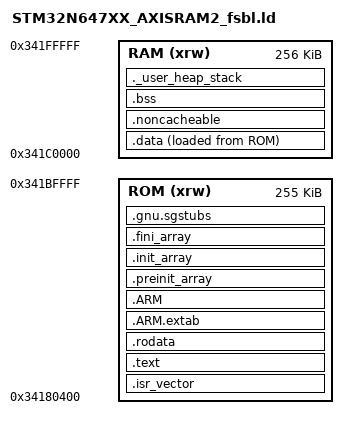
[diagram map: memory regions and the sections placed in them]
/*
******************************************************************************
**
** @file        : STM32N647XX_AXISRAM2_fsbl.ld
**
** @author      : GPM Application Team
**
** @brief       : Linker script for STM32N647XX Device from STM32N6 series
**                      512 KBytes RAM
**
**                Set heap size, stack size and stack location according
**                to application requirements.
**
**                Set memory bank area and size if external memory is used
**
**  Target      : STMicroelectronics STM32
**
**  Distribution: The file is distributed as is, without any warranty
**                of any kind.
**
******************************************************************************
** @attention
**
** Copyright (c) 2023 STMicroelectronics.
** All rights reserved.
**
** This software is licensed under terms that can be found in the LICENSE file
** in the root directory of this software component.
** If no LICENSE file comes with this software, it is provided AS-IS.
**
******************************************************************************
*/

/* Entry Point */
ENTRY(Reset_Handler)

/* Highest address of the user mode stack */
_estack = ORIGIN(RAM) + LENGTH(RAM); /* end of "RAM" Ram type memory */
_sstack = _estack - _Min_Stack_Size;

_Min_Heap_Size = 0x200; /* required amount of heap */
_Min_Stack_Size = 0x800; /* required amount of stack */

/* Memories definition */
MEMORY
{
  ROM    (xrw)    : ORIGIN = 0x34180400,   LENGTH = 255K
  RAM    (xrw)    : ORIGIN = 0x341C0000,   LENGTH = 256K
}

/* Sections */
SECTIONS
{
  /* The startup code into "RAM" Ram type memory */
  .isr_vector :
  {
    . = ALIGN(4);
    KEEP(*(.isr_vector)) /* Startup code */
    . = ALIGN(4);
  } >ROM

  /* The program code and other data into "RAM" Ram type memory */
  .text :
  {
    . = ALIGN(4);
    *(.text)           /* .text sections (code) */
    *(.text*)          /* .text* sections (code) */
    *(.glue_7)         /* glue arm to thumb code */
    *(.glue_7t)        /* glue thumb to arm code */
    *(.eh_frame)
    *(.RamFunc)        /* .RamFunc sections */
    *(.RamFunc*)       /* .RamFunc* sections */

    KEEP (*(.init))
    KEEP (*(.fini))

    . = ALIGN(4);
    _etext = .;        /* define a global symbols at end of code */
  } >ROM

  /* Constant data into "RAM" Ram type memory */
  .rodata :
  {
    . = ALIGN(4);
    *(.rodata)         /* .rodata sections (constants, strings, etc.) */
    *(.rodata*)        /* .rodata* sections (constants, strings, etc.) */
    . = ALIGN(4);
  } >ROM

  .ARM.extab   (READONLY) : /* The READONLY keyword is only supported in GCC11 and later, remove it if using GCC10 or earlier. */
   {
    . = ALIGN(4);
    *(.ARM.extab* .gnu.linkonce.armextab.*)
    . = ALIGN(4);
  } >ROM

  .ARM (READONLY) : /* The READONLY keyword is only supported in GCC11 and later, remove it if using GCC10 or earlier. */
   {
    . = ALIGN(4);
    __exidx_start = .;
    *(.ARM.exidx*)
    __exidx_end = .;
    . = ALIGN(4);
  } >ROM

  .preinit_array     (READONLY) : /* The READONLY keyword is only supported in GCC11 and later, remove it if using GCC10 or earlier. */
  {
    . = ALIGN(4);
    PROVIDE_HIDDEN (__preinit_array_start = .);
    KEEP (*(.preinit_array*))
    PROVIDE_HIDDEN (__preinit_array_end = .);
    . = ALIGN(4);
  } >ROM

  .init_array (READONLY) : /* The READONLY keyword is only supported in GCC11 and later, remove it if using GCC10 or earlier. */
  {
    . = ALIGN(4);
    PROVIDE_HIDDEN (__init_array_start = .);
    KEEP (*(SORT(.init_array.*)))
    KEEP (*(.init_array*))
    PROVIDE_HIDDEN (__init_array_end = .);
    . = ALIGN(4);
  } >ROM

  .fini_array (READONLY) : /* The READONLY keyword is only supported in GCC11 and later, remove it if using GCC10 or earlier. */
  {
    . = ALIGN(4);
    PROVIDE_HIDDEN (__fini_array_start = .);
    KEEP (*(SORT(.fini_array.*)))
    KEEP (*(.fini_array*))
    PROVIDE_HIDDEN (__fini_array_end = .);
    . = ALIGN(4);
  } >ROM

  /* Used by the startup to initialize data */
  _sidata = LOADADDR(.data);

  /* Initialized data sections into "RAM" Ram type memory */
  .data :
  {
    . = ALIGN(4);
    _sdata = .;        /* create a global symbol at data start */
    *(.data)           /* .data sections */
    *(.data*)          /* .data* sections */

    . = ALIGN(4);
    _edata = .;        /* define a global symbol at data end */

  } >RAM AT> ROM

  .noncacheable :
  {
    . = ALIGN(8);
    __snoncacheable = .;/* create symbol for start of section */
    KEEP(*(.noncacheable))
    . = ALIGN(8);
    __enoncacheable = .;  /* create symbol for end of section */
  } > RAM


  .gnu.sgstubs :
  {
    . = ALIGN(4);
    *(.gnu.sgstubs*)   /* Secure Gateway stubs */
    . = ALIGN(4);
  } >ROM
  /* Uninitialized data section into "RAM" Ram type memory */
  . = ALIGN(4);
  .bss :
  {
    /* This is used by the startup in order to initialize the .bss section */
    _sbss = .;         /* define a global symbol at bss start */
    __bss_start__ = _sbss;
    *(.bss)
    *(.bss*)
    *(COMMON)

    . = ALIGN(4);
    _ebss = .;         /* define a global symbol at bss end */
    __bss_end__ = _ebss;
  } >RAM

  /* User_heap_stack section, used to check that there is enough "RAM" Ram  type memory left */
  ._user_heap_stack :
  {
    . = ALIGN(8);
    PROVIDE ( end = . );
    PROVIDE ( _end = . );
    . = . + _Min_Heap_Size;
    . = . + _Min_Stack_Size;
    . = ALIGN(8);
  } >RAM

  /* Remove information from the compiler libraries */
  /DISCARD/ :
  {
    libc.a ( * )
    libm.a ( * )
    libgcc.a ( * )
  }

  .ARM.attributes 0 : { *(.ARM.attributes) }
}
